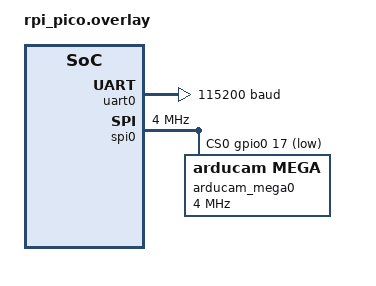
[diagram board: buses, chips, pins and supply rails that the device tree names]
/**
 * Copyright (c) 2023 Arducam Technology Co., Ltd. <www.arducam.com>
 *
 * SPDX-License-Identifier: Apache-2.0
 *
 */

&uart0{
	current-speed = <115200>;
};

&spi0 {
	clock-frequency = <4000000>;
	cs-gpios = <&gpio0 17 GPIO_ACTIVE_LOW>;
	pinctrl-names = "default";
	arducam_mega0:arducam-mega0@0 {
		compatible = "arducam,mega";
		reg = <0>;
		spi-max-frequency = <4000000>;
		status = "okay";
	};
};
